# STC32G144K246 register map
Vendor: STC; File version: 2.0
Registers are 8-bit, read-write, no defined reset value unless marked. A register's access mark holds for its fields unless they carry their own. Offsets are from the block's base; [hi:lo] are bit positions.

## Comparator — 比较器公共配置
Base 0x007EFEAE
0x00 CMPEXCFG
0xF810238 CMPCR1 ro
0xF810239 CMPCR2

## Comparator1 — 比较器 1 配置与输出状态
Base 0x007EFB70
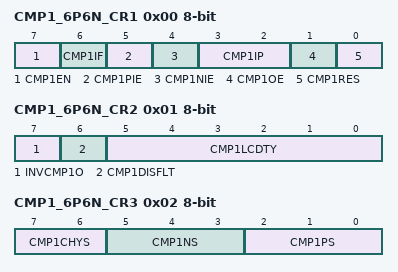
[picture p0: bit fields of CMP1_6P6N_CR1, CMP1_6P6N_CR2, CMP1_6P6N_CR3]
0x00 CMP1_6P6N_CR1 ro — 比较器1控制寄存器1
  [7] CMP1EN — 比较器模块使能位
    0=关闭比较功能; 1=使能比较功能
  [6] CMP1IF — 比较器1 中断标志位。当CMP1PIE 或CMP1NIE 被使能后，若产生相应的中断信号，硬件自 动将CMP1IF 置1，并向CPU 提出中断请求。此标志位必须用户软件向此位写0 清零。
  [5] CMP1PIE — 比较器上升沿中断使能位。
    0=禁止比较器上升沿中断。; 1=使能比较器上升沿中断。使能比较器的比较结果由0 变成1 时产生中断请求。
  [4] CMP1NIE — 比较器下降沿中断使能位。
    0=禁止比较器下降沿中断。; 1=使能比较器下降沿中断。使能比较器的比较结果由1 变成0 时产生中断请求。
  [3:2] CMP1IP — 比较器1 中断优先级设置。
    0=比较器1 中断为最低优先级。; 1=比较器1 中断为较低优先级。; 2=比较器1 中断为较高优先级。; 3=比较器1 中断为最高优先级。
  [1] CMP1OE — 比较器结果输出控制位
    0=禁止比较器结果输出; 1=使能比较器结果输出。
  [0] CMP1RES — 比较器的比较结果。此位为只读。
    0=表示CMP1+的电平低于CMP1-的电平; 1=表示CMP1+的电平高于CMP1-的电平
0x01 CMP1_6P6N_CR2 ro — 比较器1控制寄存器2
  [7] INVCMP1O — 比较器结果输出控制
    0=比较器结果正向输出。若CMP1RES 为0，则输出低电平，反之输出高电平。; 1=比较器结果反向输出。若CMP1RES 为0，则输出高电平，反之输出低电平。
  [6] CMP1DISFLT — 模拟滤波功能控制
    0=使能0.1us 模拟滤波功能; 1=关闭0.1us 模拟滤波功能，可略微提高比较器的比较速度。
  [5:0] CMP1LCDTY — 数字滤波功能控制 数字滤波功能即为数字信号去抖动功能。当比较结果发生上升沿或者下降沿变化时，比较器侦测变 化后的信号必须维持LCDTY 所设置的CPU 时钟数不发生变化，才认为数据变化是有效的；否 则将视同信号无变化。 注意：当使能数字滤波功能后，芯片内部实际的等待时钟需额外增加两个状态机切换时间，
0x02 CMP1_6P6N_CR3 ro — 比较器1控制寄存器3
  [7:6] CMP1CHYS — 比较器DC 迟滞输入选择
  [5:3] CMP1NS — 比较器负端输入选择
    0=P3.6; 1=P5.1; 2=OP2O; 3=1.19V; 4=DAC1O; 5=DAC2O
  [2:0] CMP1PS — 比较器正端输入选择
    0=P3.7; 1=P5.0; 2=OP1O; 3=ADCIN; 4=DAC1O; 5=DAC2O
0x03 CMP1_6P6N_CR4 ro — 比较器1控制寄存器4
  [1:0] CMP1O_S — 比较器输出端口选择
    0=P3.4; 1=P4.1; 2=Value_2; 3=Value_3

## PGA1 — 可编程增益放大器 / 运放 1
Base 0x007EF600
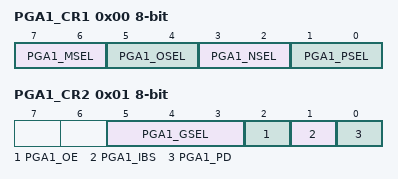
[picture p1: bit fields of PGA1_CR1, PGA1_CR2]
0x00 PGA1_CR1 — 运放1控制寄存器1
  [7:6] PGA1_MSEL — PGA1工作模式选择寄存器
    0=通用运放模式; 1=缓冲模式; 2=反相放大模式; 3=非反相放大模式
  [5:4] PGA1_OSEL — PGA1输出端口选择寄存器
    0=P0.7; 1=P0.0; 2=P7.4; 3=P6.3
  [3:2] PGA1_NSEL — PGA1负极端口选择寄存器
    0=P0.5; 1=P0.4; 2=P6.1; 3=DAC1O
  [1:0] PGA1_PSEL — PGA1正极端口选择寄存器
    0=P0.4; 1=P0.5; 2=P6.0; 3=DAC1O
0x01 PGA1_CR2 — 运放1控制寄存器2
  [5:3] PGA1_GSEL — PGA1增益控制寄存器
    0=反相放大增益倍数：N/A；非反相放大增益倍数：N/A; 1=反相放大增益倍数：1；非反相放大增益倍数：2; 2=反相放大增益倍数：2；非反相放大增益倍数：3; 3=反相放大增益倍数：4；非反相放大增益倍数：5; 4=反相放大增益倍数：8；非反相放大增益倍数：9; 5=反相放大增益倍数：16；非反相放大增益倍数：17; 6=反相放大增益倍数：32；非反相放大增益倍数：33; 7=反相放大增益倍数：48；非反相放大增益倍数：49
  [2] PGA1_OE — PGA1 输出控制位
    0=禁止PGA1 输出; 1=允许PGA1 输出
  [1] PGA1_IBS — PGA1 偏压电流大小选择
    0=正常电流大小; 1=电流倍增
  [0] PGA1_PD — PGA1 电源控制
    0=禁止掉电（使能PGA1）; 1=使能掉电（关闭PGA1）

## Comparator2 — 比较器 2 配置与输出状态
Base 0x007EFB74
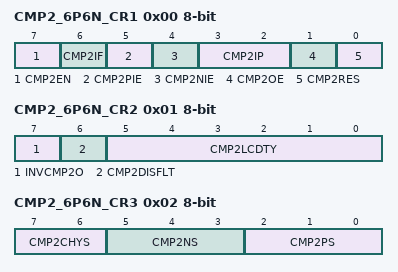
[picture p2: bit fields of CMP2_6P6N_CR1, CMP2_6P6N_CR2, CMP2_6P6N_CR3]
0x00 CMP2_6P6N_CR1 ro — 比较器2控制寄存器1
  [7] CMP2EN — 比较器模块使能位
    0=关闭比较功能; 1=使能比较功能
  [6] CMP2IF — 比较器2 中断标志位。当CMP2PIE 或CMP2NIE 被使能后，若产生相应的中断信号，硬件自 动将CMP2IF 置1，并向CPU 提出中断请求。此标志位必须用户软件向此位写0 清零。
  [5] CMP2PIE — 比较器2 上升沿中断使能位。
    0=禁止比较器2 上升沿中断。; 1=使能比较器2 上升沿中断。使能比较器2 的比较结果由0 变成1 时产生中断请求。
  [4] CMP2NIE — 比较器2 下降沿中断使能位。
    0=禁止比较器2 下降沿中断。; 1=使能比较器2 下降沿中断。使能比较器2 的比较结果由1 变成0 时产生中断请求。
  [3:2] CMP2IP — 比较器2 中断优先级设置。
    0=比较器2 中断为最低优先级。; 1=比较器2 中断为较低优先级。; 2=比较器2 中断为较高优先级。; 3=比较器2 中断为最高优先级。
  [1] CMP2OE — 比较器结果输出控制位
    0=禁止比较器结果输出; 1=使能比较器结果输出。
  [0] CMP2RES — 比较器的比较结果。此位为只读。
    0=表示CMP2+的电平低于CMP2-的电平; 1=表示CMP2+的电平高于CMP2-的电平
0x01 CMP2_6P6N_CR2 ro — 比较器2控制寄存器2
  [7] INVCMP2O — 比较器结果输出控制
    0=比较器结果正向输出。若CMP2RES 为0，则输出低电平，反之输出高电平。; 1=比较器结果反向输出。若CMP2RES 为0，则输出高电平，反之输出低电平。
  [6] CMP2DISFLT — 模拟滤波功能控制
    0=使能0.1us 模拟滤波功能; 1=关闭0.1us 模拟滤波功能，可略微提高比较器的比较速度。
  [5:0] CMP2LCDTY — 数字滤波功能控制 数字滤波功能即为数字信号去抖动功能。当比较结果发生上升沿或者下降沿变化时，比较器侦测变 化后的信号必须维持LCDTY 所设置的CPU 时钟数不发生变化，才认为数据变化是有效的；否 则将视同信号无变化。 注意：当使能数字滤波功能后，芯片内部实际的等待时钟需额外增加两个状态机切换时间，
0x02 CMP2_6P6N_CR3 ro — 比较器2控制寄存器3
  [7:6] CMP2CHYS — 比较器DC 迟滞输入选择
  [5:3] CMP2NS — 比较器负端输入选择
    0=P6.6; 1=P1.1; 2=OP3O; 3=1.19V; 4=DAC1O; 5=DAC2O
  [2:0] CMP2PS — 比较器正端输入选择
    0=P6.7; 1=P1.0; 2=OP2O; 3=ADCIN; 4=DAC1O; 5=DAC2O
0x03 CMP2_6P6N_CR4 ro — 比较器2控制寄存器4
  [1:0] CMP2O_S — 比较器输出端口选择
    0=P4.7; 1=P4.0; 2=Value_2; 3=Value_3
